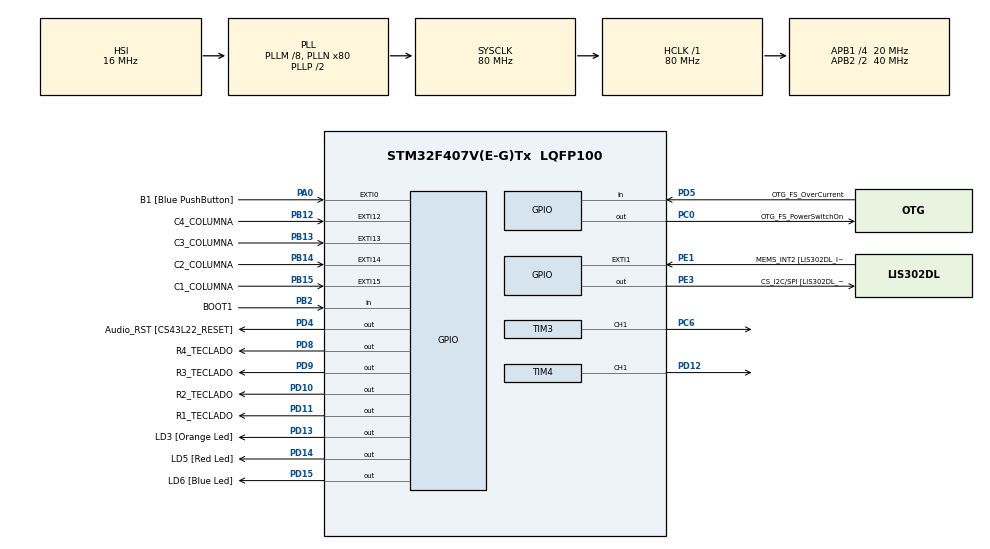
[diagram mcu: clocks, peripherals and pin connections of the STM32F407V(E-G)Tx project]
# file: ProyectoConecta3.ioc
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Dma.Request0=TIM4_CH1
Dma.Request1=TIM8_CH4/TRIG/COM
Dma.TIM4_CH1.0.Direction=DMA_MEMORY_TO_PERIPH
Dma.TIM4_CH1.0.FIFOMode=DMA_FIFOMODE_DISABLE
Dma.TIM4_CH1.0.Instance=DMA1_Stream0
Dma.TIM4_CH1.0.MemDataAlignment=DMA_MDATAALIGN_HALFWORD
Dma.TIM4_CH1.0.MemInc=DMA_MINC_ENABLE
Dma.TIM4_CH1.0.Mode=DMA_NORMAL
Dma.TIM4_CH1.0.PeriphDataAlignment=DMA_PDATAALIGN_HALFWORD
Dma.TIM4_CH1.0.PeriphInc=DMA_PINC_DISABLE
Dma.TIM4_CH1.0.Priority=DMA_PRIORITY_HIGH
Dma.TIM8_CH4/TRIG/COM.1.Direction=DMA_PERIPH_TO_MEMORY
Dma.TIM8_CH4/TRIG/COM.1.FIFOMode=DMA_FIFOMODE_DISABLE
Dma.TIM8_CH4/TRIG/COM.1.Instance=DMA2_Stream7
Dma.TIM8_CH4/TRIG/COM.1.MemDataAlignment=DMA_MDATAALIGN_HALFWORD
Dma.TIM8_CH4/TRIG/COM.1.MemInc=DMA_MINC_ENABLE
Dma.TIM8_CH4/TRIG/COM.1.Mode=DMA_NORMAL
Dma.TIM8_CH4/TRIG/COM.1.PeriphDataAlignment=DMA_PDATAALIGN_HALFWORD
Dma.TIM8_CH4/TRIG/COM.1.PeriphInc=DMA_PINC_DISABLE
Dma.TIM8_CH4/TRIG/COM.1.Priority=DMA_PRIORITY_LOW
Mcu.Family=STM32F4
Mcu.Name=STM32F407V(E-G)Tx
Mcu.Package=LQFP100
NVIC.DMA1_Stream0_IRQn=true\:0\:0\:false\:false\:true\:false\:true\:true
NVIC.DMA2_Stream7_IRQn=true\:0\:0\:false\:false\:true\:false\:true\:true
NVIC.EXTI0_IRQn=true\:0\:0\:false\:false\:true\:true\:true\:true
NVIC.EXTI15_10_IRQn=true\:0\:0\:false\:false\:true\:true\:true\:true
NVIC.PriorityGroup=NVIC_PRIORITYGROUP_0
NVIC.TIM8_TRG_COM_TIM14_IRQn=true\:0\:0\:false\:false\:true\:true\:true\:true
PA0-WKUP.GPIO_Label=B1 [Blue PushButton]
PA0-WKUP.Signal=GPXTI0
PA10.GPIO_Label=OTG_FS_ID
PA10.GPIO_Mode=GPIO_MODE_AF_PP
PA10.GPIO_PuPd=GPIO_NOPULL
PA10.GPIO_Speed=GPIO_SPEED_FREQ_LOW
PA10.Signal=USB_OTG_FS_ID
PA11.GPIO_Label=OTG_FS_DM
PA11.GPIO_Mode=GPIO_MODE_AF_PP
PA11.GPIO_PuPd=GPIO_NOPULL
PA11.GPIO_Speed=GPIO_SPEED_FREQ_LOW
PA11.Signal=USB_OTG_FS_DM
PA12.GPIO_Label=OTG_FS_DP
PA12.GPIO_Mode=GPIO_MODE_AF_PP
PA12.GPIO_PuPd=GPIO_NOPULL
PA12.GPIO_Speed=GPIO_SPEED_FREQ_LOW
PA12.Signal=USB_OTG_FS_DP
PA13.GPIO_Label=SWDIO
PA13.Signal=SYS_JTMS-SWDIO
PA14.GPIO_Label=SWCLK
PA14.Signal=SYS_JTCK-SWCLK
PA4.GPIO_Label=I2S3_WS [CS43L22_LRCK]
PA4.GPIO_Mode=GPIO_MODE_AF_PP
PA4.GPIO_PuPd=GPIO_NOPULL
PA4.GPIO_Speed=GPIO_SPEED_FREQ_LOW
PA4.Signal=I2S3_WS
PA5.GPIO_Label=SPI1_SCK [LIS302DL_SCL/SPC]
PA5.GPIO_Mode=GPIO_MODE_AF_PP
PA5.GPIO_PuPd=GPIO_NOPULL
PA5.GPIO_Speed=GPIO_SPEED_FREQ_LOW
PA5.Signal=SPI1_SCK
PA9.GPIO_Label=VBUS_FS
PA9.GPIO_Mode=GPIO_MODE_INPUT
PA9.GPIO_PuPd=GPIO_NOPULL
PA9.Signal=USB_OTG_FS_VBUS
PB10.GPIO_Label=CLK_IN [MP45DT02_CLK]
PB10.GPIO_Mode=GPIO_MODE_AF_PP
PB10.GPIO_PuPd=GPIO_NOPULL
PB10.GPIO_Speed=GPIO_SPEED_FREQ_LOW
PB10.Signal=I2S2_CK
PB12.GPIO_Label=C4_COLUMNA
PB12.GPIO_ModeDefaultEXTI=GPIO_MODE_IT_FALLING
PB12.GPIO_PuPd=GPIO_PULLUP
PB12.Signal=GPXTI12
PB13.GPIO_Label=C3_COLUMNA
PB13.GPIO_ModeDefaultEXTI=GPIO_MODE_IT_FALLING
PB13.GPIO_PuPd=GPIO_PULLUP
PB13.Signal=GPXTI13
PB14.GPIO_Label=C2_COLUMNA
PB14.GPIO_ModeDefaultEXTI=GPIO_MODE_IT_FALLING
PB14.GPIO_PuPd=GPIO_PULLUP
PB14.Signal=GPXTI14
PB15.GPIO_Label=C1_COLUMNA
PB15.GPIO_ModeDefaultEXTI=GPIO_MODE_IT_FALLING
PB15.GPIO_PuPd=GPIO_PULLUP
PB15.Signal=GPXTI15
PB2.GPIO_Label=BOOT1
PB2.GPIO_Mode=GPIO_MODE_INPUT
PB2.GPIO_PuPd=GPIO_NOPULL
PB2.Signal=GPIO_Input
PB3.GPIO_Label=SWO
PB3.Signal=SYS_JTDO-SWO
PB6.GPIO_Label=Audio_SCL [CS43L22_SCL]
PB6.GPIO_Mode=GPIO_MODE_AF_OD
PB6.GPIO_PuPd=GPIO_NOPULL
PB6.GPIO_Speed=GPIO_SPEED_FREQ_LOW
PB6.Signal=I2C1_SCL
PC0.GPIO_Label=OTG_FS_PowerSwitchOn
PC0.GPIO_PuPd=GPIO_NOPULL
PC0.GPIO_Speed=GPIO_SPEED_FREQ_LOW
PC0.PinState=GPIO_PIN_SET
PC0.Signal=GPIO_Output
PC10.GPIO_Label=I2S3_SCK [CS43L22_SCLK]
PC10.GPIO_Mode=GPIO_MODE_AF_PP
PC10.GPIO_PuPd=GPIO_NOPULL
PC10.GPIO_Speed=GPIO_SPEED_FREQ_LOW
PC10.Signal=I2S3_CK
PC12.GPIO_Label=I2S3_SD [CS43L22_SDIN]
PC12.GPIO_Mode=GPIO_MODE_AF_PP
PC12.GPIO_PuPd=GPIO_NOPULL
PC12.GPIO_Speed=GPIO_SPEED_FREQ_LOW
PC12.Signal=I2S3_SD
PC14-OSC32_IN.GPIO_Label=PC14-OSC32_IN
PC14-OSC32_IN.Signal=RCC_OSC32_IN
PC15-OSC32_OUT.GPIO_Label=PC15-OSC32_OUT
PC15-OSC32_OUT.Signal=RCC_OSC32_OUT
PC3.GPIO_Label=PDM_OUT [MP45DT02_DOUT]
PC3.GPIO_Mode=GPIO_MODE_AF_PP
PC3.GPIO_PuPd=GPIO_NOPULL
PC3.GPIO_Speed=GPIO_SPEED_FREQ_LOW
PC3.Signal=I2S2_SD
PC6.Signal=S_TIM3_CH1
PC7.GPIO_Label=I2S3_MCK [CS43L22_MCLK]
PC7.GPIO_Mode=GPIO_MODE_AF_PP
PC7.GPIO_PuPd=GPIO_NOPULL
PC7.GPIO_Speed=GPIO_SPEED_FREQ_LOW
PC7.Signal=I2S3_MCK
PD10.GPIO_Label=R2_TECLADO
PD10.GPIO_ModeDefaultOutputPP=GPIO_MODE_OUTPUT_OD
PD10.GPIO_PuPd=GPIO_NOPULL
PD10.Signal=GPIO_Output
PD11.GPIO_Label=R1_TECLADO
PD11.GPIO_ModeDefaultOutputPP=GPIO_MODE_OUTPUT_OD
PD11.GPIO_PuPd=GPIO_NOPULL
PD11.Signal=GPIO_Output
PD12.GPIO_Speed=GPIO_SPEED_FREQ_HIGH
PD12.Signal=S_TIM4_CH1
PD13.GPIO_Label=LD3 [Orange Led]
PD13.GPIO_PuPd=GPIO_NOPULL
PD13.GPIO_Speed=GPIO_SPEED_FREQ_LOW
PD13.Signal=GPIO_Output
PD14.GPIO_Label=LD5 [Red Led]
PD14.GPIO_PuPd=GPIO_NOPULL
PD14.GPIO_Speed=GPIO_SPEED_FREQ_LOW
PD14.Signal=GPIO_Output
PD15.GPIO_Label=LD6 [Blue Led]
PD15.GPIO_PuPd=GPIO_NOPULL
PD15.GPIO_Speed=GPIO_SPEED_FREQ_LOW
PD15.Signal=GPIO_Output
PD4.GPIO_Label=Audio_RST [CS43L22_RESET]
PD4.GPIO_PuPd=GPIO_NOPULL
PD4.GPIO_Speed=GPIO_SPEED_FREQ_LOW
PD4.Signal=GPIO_Output
PD5.GPIO_Label=OTG_FS_OverCurrent
PD5.GPIO_Mode=GPIO_MODE_INPUT
PD5.GPIO_PuPd=GPIO_NOPULL
PD5.Signal=GPIO_Input
PD8.GPIO_Label=R4_TECLADO
PD8.GPIO_ModeDefaultOutputPP=GPIO_MODE_OUTPUT_OD
PD8.GPIO_PuPd=GPIO_NOPULL
PD8.Signal=GPIO_Output
PD9.GPIO_Label=R3_TECLADO
PD9.GPIO_ModeDefaultOutputPP=GPIO_MODE_OUTPUT_OD
PD9.GPIO_PuPd=GPIO_NOPULL
PD9.Signal=GPIO_Output
PE1.GPIO_Label=MEMS_INT2 [LIS302DL_INT2]
PE1.GPIO_ModeDefaultEXTI=GPIO_MODE_EVT_RISING
PE1.GPIO_PuPd=GPIO_NOPULL
PE1.Signal=GPXTI1
PE3.GPIO_Label=CS_I2C/SPI [LIS302DL_CS_I2C/SPI]
PE3.GPIO_PuPd=GPIO_NOPULL
PE3.GPIO_Speed=GPIO_SPEED_FREQ_LOW
PE3.Signal=GPIO_Output
PE7.Signal=S_TIM1_ETR
PH0-OSC_IN.GPIO_Label=PH0-OSC_IN
PH0-OSC_IN.Signal=RCC_OSC_IN
PH1-OSC_OUT.GPIO_Label=PH1-OSC_OUT
PH1-OSC_OUT.Signal=RCC_OSC_OUT
ProjectManager.HeapSize=0x200
ProjectManager.StackSize=0x400
ProjectManager.TargetToolchain=STM32CubeIDE
RCC.48MHZClocksFreq_Value=22857142.85714286
RCC.AHBFreq_Value=80000000
RCC.APB1CLKDivider=RCC_HCLK_DIV4
RCC.APB1Freq_Value=20000000
RCC.APB1TimFreq_Value=40000000
RCC.APB2CLKDivider=RCC_HCLK_DIV2
RCC.APB2Freq_Value=40000000
RCC.APB2TimFreq_Value=80000000
RCC.CortexFreq_Value=80000000
RCC.HCLKFreq_Value=80000000
RCC.HSE_VALUE=8000000
RCC.HSI_VALUE=16000000
RCC.LSE_VALUE=32768
RCC.PLLM=8
RCC.PLLN=80
RCC.PLLQ=7
RCC.SYSCLKFreq_VALUE=80000000
RCC.SYSCLKSource=RCC_SYSCLKSOURCE_PLLCLK
RCC.VCOOutputFreq_Value=160000000
SH.S_TIM1_ETR.0=TIM1_ETR
SH.S_TIM3_CH1.0=TIM3_CH1,PWM Generation1 CH1
SH.S_TIM4_CH1.0=TIM4_CH1,PWM Generation1 CH1
TIM14.AutoReloadPreload=TIM_AUTORELOAD_PRELOAD_ENABLE
TIM14.Period=9
TIM14.Prescaler=39999
TIM3.AutoReloadPreload=TIM_AUTORELOAD_PRELOAD_ENABLE
TIM3.Channel-PWM\ Generation1\ CH1=TIM_CHANNEL_1
TIM3.Period=28408
TIM3.Prescaler=2
TIM4.Channel-PWM\ Generation1\ CH1=TIM_CHANNEL_1
TIM4.Period=49
VP_TIM14_VS_ClockSourceINT.Mode=Enable_Timer
VP_TIM1_VS_ClockSourceINT.Mode=Internal
VP_TIM3_VS_ClockSourceINT.Mode=Internal
VP_TIM4_VS_ClockSourceINT.Mode=Internal
VP_TIM8_VS_ClockSourceINT.Mode=Internal
board=STM32F407G-DISC1

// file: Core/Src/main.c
/* USER CODE BEGIN Header */
/**
  ******************************************************************************
  * @file           : main.c
  * @brief          : Main program body
  ******************************************************************************
  * @attention
  *
  * Copyright (c) 2026 STMicroelectronics.
  * All rights reserved.
  *
  * This software is licensed under terms that can be found in the LICENSE file
  * in the root directory of this software component.
  * If no LICENSE file comes with this software, it is provided AS-IS.
  *
  ******************************************************************************
  */
/* USER CODE END Header */
#include "main.h"

/* USER CODE BEGIN Includes */
#include "Teclado.h"
#include "Leds.h"
#include "Conecta3.h"
/* USER CODE END Includes */

TIM_HandleTypeDef htim1;
TIM_HandleTypeDef htim3;
TIM_HandleTypeDef htim4;
TIM_HandleTypeDef htim8;
TIM_HandleTypeDef htim14;
DMA_HandleTypeDef hdma_tim4_ch1;
DMA_HandleTypeDef hdma_tim8_ch4_trig_com;

void SystemClock_Config(void);
static void MX_GPIO_Init(void);
static void MX_DMA_Init(void);
static void MX_TIM4_Init(void);
static void MX_TIM1_Init(void);
static void MX_TIM8_Init(void);
static void MX_TIM14_Init(void);
static void MX_TIM3_Init(void);

int main(void)
{

  /* MCU Configuration--------------------------------------------------------*/

  /* Reset of all peripherals, Initializes the Flash interface and the Systick. */
  HAL_Init();

  /* Configure the system clock */
  SystemClock_Config();

  /* Initialize all configured peripherals */
  MX_GPIO_Init();
  MX_DMA_Init();
  MX_TIM4_Init();
  MX_TIM1_Init();
  MX_TIM8_Init();
  MX_TIM14_Init();
  MX_TIM3_Init();
  /* USER CODE BEGIN 2 */

   // HAL_Delay(50); // Le damos tiempo a los LEDs para despertar

    Teclado_Init();
    Juego_Init();  // Esto inicializa la matriz virtual y la física
   //HAL_TIM_Base_Start_IT(&htim14);

  /* USER CODE END 2 */

  /* Infinite loop */
  /* USER CODE BEGIN WHILE */
    while (1)
      {
    	/* Actualiza los registros internos de sensado del teclado matricial */
    	      Teclado_Update();

    	      /* Tarea asincrónica del refresco gráfico y rutinas temporales de juego */
    	      Juego_Actualizar();

    	      /* Captura el evento de la última pulsación filtrada */
    	      uint8_t tecla = Teclado_GetUltimaTecla();

    	      /* Despacha el código de la tecla hacia el subsistema lógico */
    	      if (tecla != 0) {
    	          Juego_ProcesarEntrada(tecla);
    	      }
      }
    /* USER CODE END WHILE */

}

void SystemClock_Config(void)
{
  RCC_OscInitTypeDef RCC_OscInitStruct = {0};
  RCC_ClkInitTypeDef RCC_ClkInitStruct = {0};

  /** Configure the main internal regulator output voltage
  */
  __HAL_RCC_PWR_CLK_ENABLE();
  __HAL_PWR_VOLTAGESCALING_CONFIG(PWR_REGULATOR_VOLTAGE_SCALE1);

  /** Initializes the RCC Oscillators according to the specified parameters
  * in the RCC_OscInitTypeDef structure.
  */
  RCC_OscInitStruct.OscillatorType = RCC_OSCILLATORTYPE_HSI;
  RCC_OscInitStruct.HSIState = RCC_HSI_ON;
  RCC_OscInitStruct.HSICalibrationValue = RCC_HSICALIBRATION_DEFAULT;
  RCC_OscInitStruct.PLL.PLLState = RCC_PLL_ON;
  RCC_OscInitStruct.PLL.PLLSource = RCC_PLLSOURCE_HSI;
  RCC_OscInitStruct.PLL.PLLM = 8;
  RCC_OscInitStruct.PLL.PLLN = 80;
  RCC_OscInitStruct.PLL.PLLP = RCC_PLLP_DIV2;
  RCC_OscInitStruct.PLL.PLLQ = 7;
  if (HAL_RCC_OscConfig(&RCC_OscInitStruct) != HAL_OK)
  {
    Error_Handler();
  }

  /** Initializes the CPU, AHB and APB buses clocks
  */
  RCC_ClkInitStruct.ClockType = RCC_CLOCKTYPE_HCLK|RCC_CLOCKTYPE_SYSCLK
                              |RCC_CLOCKTYPE_PCLK1|RCC_CLOCKTYPE_PCLK2;
  RCC_ClkInitStruct.SYSCLKSource = RCC_SYSCLKSOURCE_PLLCLK;
  RCC_ClkInitStruct.AHBCLKDivider = RCC_SYSCLK_DIV1;
  RCC_ClkInitStruct.APB1CLKDivider = RCC_HCLK_DIV4;
  RCC_ClkInitStruct.APB2CLKDivider = RCC_HCLK_DIV2;

  if (HAL_RCC_ClockConfig(&RCC_ClkInitStruct, FLASH_LATENCY_2) != HAL_OK)
  {
    Error_Handler();
  }
}

static void MX_TIM1_Init(void)
{

  TIM_ClockConfigTypeDef sClockSourceConfig = {0};
  TIM_MasterConfigTypeDef sMasterConfig = {0};

  htim1.Instance = TIM1;
  htim1.Init.Prescaler = 0;
  htim1.Init.CounterMode = TIM_COUNTERMODE_UP;
  htim1.Init.Period = 65535;
  htim1.Init.ClockDivision = TIM_CLOCKDIVISION_DIV1;
  htim1.Init.RepetitionCounter = 0;
  htim1.Init.AutoReloadPreload = TIM_AUTORELOAD_PRELOAD_DISABLE;
  if (HAL_TIM_Base_Init(&htim1) != HAL_OK)
  {
    Error_Handler();
  }
  sClockSourceConfig.ClockSource = TIM_CLOCKSOURCE_INTERNAL;
  if (HAL_TIM_ConfigClockSource(&htim1, &sClockSourceConfig) != HAL_OK)
  {
    Error_Handler();
  }
  sMasterConfig.MasterOutputTrigger = TIM_TRGO_RESET;
  sMasterConfig.MasterSlaveMode = TIM_MASTERSLAVEMODE_DISABLE;
  if (HAL_TIMEx_MasterConfigSynchronization(&htim1, &sMasterConfig) != HAL_OK)
  {
    Error_Handler();
  }

}

static void MX_TIM3_Init(void)
{

  TIM_ClockConfigTypeDef sClockSourceConfig = {0};
  TIM_MasterConfigTypeDef sMasterConfig = {0};
  TIM_OC_InitTypeDef sConfigOC = {0};

  htim3.Instance = TIM3;
  htim3.Init.Prescaler = 2;
  htim3.Init.CounterMode = TIM_COUNTERMODE_UP;
  htim3.Init.Period = 28408;
  htim3.Init.ClockDivision = TIM_CLOCKDIVISION_DIV1;
  htim3.Init.AutoReloadPreload = TIM_AUTORELOAD_PRELOAD_ENABLE;
  if (HAL_TIM_Base_Init(&htim3) != HAL_OK)
  {
    Error_Handler();
  }
  sClockSourceConfig.ClockSource = TIM_CLOCKSOURCE_INTERNAL;
  if (HAL_TIM_ConfigClockSource(&htim3, &sClockSourceConfig) != HAL_OK)
  {
    Error_Handler();
  }
  if (HAL_TIM_PWM_Init(&htim3) != HAL_OK)
  {
    Error_Handler();
  }
  sMasterConfig.MasterOutputTrigger = TIM_TRGO_RESET;
  sMasterConfig.MasterSlaveMode = TIM_MASTERSLAVEMODE_DISABLE;
  if (HAL_TIMEx_MasterConfigSynchronization(&htim3, &sMasterConfig) != HAL_OK)
  {
    Error_Handler();
  }
  sConfigOC.OCMode = TIM_OCMODE_PWM1;
  sConfigOC.Pulse = 0;
  sConfigOC.OCPolarity = TIM_OCPOLARITY_HIGH;
  sConfigOC.OCFastMode = TIM_OCFAST_DISABLE;
  if (HAL_TIM_PWM_ConfigChannel(&htim3, &sConfigOC, TIM_CHANNEL_1) != HAL_OK)
  {
    Error_Handler();
  }
  HAL_TIM_MspPostInit(&htim3);

}

static void MX_TIM4_Init(void)
{

  TIM_ClockConfigTypeDef sClockSourceConfig = {0};
  TIM_MasterConfigTypeDef sMasterConfig = {0};
  TIM_OC_InitTypeDef sConfigOC = {0};

  htim4.Instance = TIM4;
  htim4.Init.Prescaler = 0;
  htim4.Init.CounterMode = TIM_COUNTERMODE_UP;
  htim4.Init.Period = 49;
  htim4.Init.ClockDivision = TIM_CLOCKDIVISION_DIV1;
  htim4.Init.AutoReloadPreload = TIM_AUTORELOAD_PRELOAD_DISABLE;
  if (HAL_TIM_Base_Init(&htim4) != HAL_OK)
  {
    Error_Handler();
  }
  sClockSourceConfig.ClockSource = TIM_CLOCKSOURCE_INTERNAL;
  if (HAL_TIM_ConfigClockSource(&htim4, &sClockSourceConfig) != HAL_OK)
  {
    Error_Handler();
  }
  if (HAL_TIM_PWM_Init(&htim4) != HAL_OK)
  {
    Error_Handler();
  }
  sMasterConfig.MasterOutputTrigger = TIM_TRGO_RESET;
  sMasterConfig.MasterSlaveMode = TIM_MASTERSLAVEMODE_DISABLE;
  if (HAL_TIMEx_MasterConfigSynchronization(&htim4, &sMasterConfig) != HAL_OK)
  {
    Error_Handler();
  }
  sConfigOC.OCMode = TIM_OCMODE_PWM1;
  sConfigOC.Pulse = 0;
  sConfigOC.OCPolarity = TIM_OCPOLARITY_HIGH;
  sConfigOC.OCFastMode = TIM_OCFAST_DISABLE;
  if (HAL_TIM_PWM_ConfigChannel(&htim4, &sConfigOC, TIM_CHANNEL_1) != HAL_OK)
  {
    Error_Handler();
  }
  HAL_TIM_MspPostInit(&htim4);

}

static void MX_TIM8_Init(void)
{

  TIM_ClockConfigTypeDef sClockSourceConfig = {0};
  TIM_MasterConfigTypeDef sMasterConfig = {0};

  htim8.Instance = TIM8;
  htim8.Init.Prescaler = 0;
  htim8.Init.CounterMode = TIM_COUNTERMODE_UP;
  htim8.Init.Period = 65535;
  htim8.Init.ClockDivision = TIM_CLOCKDIVISION_DIV1;
  htim8.Init.RepetitionCounter = 0;
  htim8.Init.AutoReloadPreload = TIM_AUTORELOAD_PRELOAD_DISABLE;
  if (HAL_TIM_Base_Init(&htim8) != HAL_OK)
  {
    Error_Handler();
  }
  sClockSourceConfig.ClockSource = TIM_CLOCKSOURCE_INTERNAL;
  if (HAL_TIM_ConfigClockSource(&htim8, &sClockSourceConfig) != HAL_OK)
  {
    Error_Handler();
  }
  sMasterConfig.MasterOutputTrigger = TIM_TRGO_RESET;
  sMasterConfig.MasterSlaveMode = TIM_MASTERSLAVEMODE_DISABLE;
  if (HAL_TIMEx_MasterConfigSynchronization(&htim8, &sMasterConfig) != HAL_OK)
  {
    Error_Handler();
  }

}

static void MX_TIM14_Init(void)
{

  htim14.Instance = TIM14;
  htim14.Init.Prescaler = 39999;
  htim14.Init.CounterMode = TIM_COUNTERMODE_UP;
  htim14.Init.Period = 9;
  htim14.Init.ClockDivision = TIM_CLOCKDIVISION_DIV1;
  htim14.Init.AutoReloadPreload = TIM_AUTORELOAD_PRELOAD_ENABLE;
  if (HAL_TIM_Base_Init(&htim14) != HAL_OK)
  {
    Error_Handler();
  }

}

static void MX_DMA_Init(void)
{

  /* DMA controller clock enable */
  __HAL_RCC_DMA1_CLK_ENABLE();
  __HAL_RCC_DMA2_CLK_ENABLE();

  /* DMA interrupt init */
  /* DMA1_Stream0_IRQn interrupt configuration */
  HAL_NVIC_SetPriority(DMA1_Stream0_IRQn, 0, 0);
  HAL_NVIC_EnableIRQ(DMA1_Stream0_IRQn);
  /* DMA2_Stream7_IRQn interrupt configuration */
  HAL_NVIC_SetPriority(DMA2_Stream7_IRQn, 0, 0);
  HAL_NVIC_EnableIRQ(DMA2_Stream7_IRQn);

}

static void MX_GPIO_Init(void)
{
  GPIO_InitTypeDef GPIO_InitStruct = {0};

  /* GPIO Ports Clock Enable */
  __HAL_RCC_GPIOE_CLK_ENABLE();
  __HAL_RCC_GPIOC_CLK_ENABLE();
  __HAL_RCC_GPIOH_CLK_ENABLE();
  __HAL_RCC_GPIOA_CLK_ENABLE();
  __HAL_RCC_GPIOB_CLK_ENABLE();
  __HAL_RCC_GPIOD_CLK_ENABLE();

  /*Configure GPIO pin Output Level */
  HAL_GPIO_WritePin(CS_I2C_SPI_GPIO_Port, CS_I2C_SPI_Pin, GPIO_PIN_RESET);

  /*Configure GPIO pin Output Level */
  HAL_GPIO_WritePin(OTG_FS_PowerSwitchOn_GPIO_Port, OTG_FS_PowerSwitchOn_Pin, GPIO_PIN_SET);

  /*Configure GPIO pin Output Level */
  HAL_GPIO_WritePin(GPIOD, R4_TECLADO_Pin|R3_TECLADO_Pin|R2_TECLADO_Pin|R1_TECLADO_Pin
                          |LD3_Pin|LD5_Pin|LD6_Pin|Audio_RST_Pin, GPIO_PIN_RESET);

  /*Configure GPIO pin : CS_I2C_SPI_Pin */
  GPIO_InitStruct.Pin = CS_I2C_SPI_Pin;
  GPIO_InitStruct.Mode = GPIO_MODE_OUTPUT_PP;
  GPIO_InitStruct.Pull = GPIO_NOPULL;
  GPIO_InitStruct.Speed = GPIO_SPEED_FREQ_LOW;
  HAL_GPIO_Init(CS_I2C_SPI_GPIO_Port, &GPIO_InitStruct);

  /*Configure GPIO pin : OTG_FS_PowerSwitchOn_Pin */
  GPIO_InitStruct.Pin = OTG_FS_PowerSwitchOn_Pin;
  GPIO_InitStruct.Mode = GPIO_MODE_OUTPUT_PP;
  GPIO_InitStruct.Pull = GPIO_NOPULL;
  GPIO_InitStruct.Speed = GPIO_SPEED_FREQ_LOW;
  HAL_GPIO_Init(OTG_FS_PowerSwitchOn_GPIO_Port, &GPIO_InitStruct);

  /*Configure GPIO pin : PDM_OUT_Pin */
  GPIO_InitStruct.Pin = PDM_OUT_Pin;
  GPIO_InitStruct.Mode = GPIO_MODE_AF_PP;
  GPIO_InitStruct.Pull = GPIO_NOPULL;
  GPIO_InitStruct.Speed = GPIO_SPEED_FREQ_LOW;
  GPIO_InitStruct.Alternate = GPIO_AF5_SPI2;
  HAL_GPIO_Init(PDM_OUT_GPIO_Port, &GPIO_InitStruct);

  /*Configure GPIO pin : B1_Pin */
  GPIO_InitStruct.Pin = B1_Pin;
  GPIO_InitStruct.Mode = GPIO_MODE_IT_RISING;
  GPIO_InitStruct.Pull = GPIO_NOPULL;
  HAL_GPIO_Init(B1_GPIO_Port, &GPIO_InitStruct);

  /*Configure GPIO pin : I2S3_WS_Pin */
  GPIO_InitStruct.Pin = I2S3_WS_Pin;
  GPIO_InitStruct.Mode = GPIO_MODE_AF_PP;
  GPIO_InitStruct.Pull = GPIO_NOPULL;
  GPIO_InitStruct.Speed = GPIO_SPEED_FREQ_LOW;
  GPIO_InitStruct.Alternate = GPIO_AF6_SPI3;
  HAL_GPIO_Init(I2S3_WS_GPIO_Port, &GPIO_InitStruct);

  /*Configure GPIO pin : SPI1_SCK_Pin */
  GPIO_InitStruct.Pin = SPI1_SCK_Pin;
  GPIO_InitStruct.Mode = GPIO_MODE_AF_PP;
  GPIO_InitStruct.Pull = GPIO_NOPULL;
  GPIO_InitStruct.Speed = GPIO_SPEED_FREQ_LOW;
  GPIO_InitStruct.Alternate = GPIO_AF5_SPI1;
  HAL_GPIO_Init(SPI1_SCK_GPIO_Port, &GPIO_InitStruct);

  /*Configure GPIO pin : BOOT1_Pin */
  GPIO_InitStruct.Pin = BOOT1_Pin;
  GPIO_InitStruct.Mode = GPIO_MODE_INPUT;
  GPIO_InitStruct.Pull = GPIO_NOPULL;
  HAL_GPIO_Init(BOOT1_GPIO_Port, &GPIO_InitStruct);

  /*Configure GPIO pin : CLK_IN_Pin */
  GPIO_InitStruct.Pin = CLK_IN_Pin;
  GPIO_InitStruct.Mode = GPIO_MODE_AF_PP;
  GPIO_InitStruct.Pull = GPIO_NOPULL;
  GPIO_InitStruct.Speed = GPIO_SPEED_FREQ_LOW;
  GPIO_InitStruct.Alternate = GPIO_AF5_SPI2;
  HAL_GPIO_Init(CLK_IN_GPIO_Port, &GPIO_InitStruct);

  /*Configure GPIO pins : C4_COLUMNA_Pin C3_COLUMNA_Pin C2_COLUMNA_Pin C1_COLUMNA_Pin */
  GPIO_InitStruct.Pin = C4_COLUMNA_Pin|C3_COLUMNA_Pin|C2_COLUMNA_Pin|C1_COLUMNA_Pin;
  GPIO_InitStruct.Mode = GPIO_MODE_IT_FALLING;
  GPIO_InitStruct.Pull = GPIO_PULLUP;
  HAL_GPIO_Init(GPIOB, &GPIO_InitStruct);

  /*Configure GPIO pins : R4_TECLADO_Pin R3_TECLADO_Pin R2_TECLADO_Pin R1_TECLADO_Pin */
  GPIO_InitStruct.Pin = R4_TECLADO_Pin|R3_TECLADO_Pin|R2_TECLADO_Pin|R1_TECLADO_Pin;
  GPIO_InitStruct.Mode = GPIO_MODE_OUTPUT_OD;
  GPIO_InitStruct.Pull = GPIO_NOPULL;
  GPIO_InitStruct.Speed = GPIO_SPEED_FREQ_LOW;
  HAL_GPIO_Init(GPIOD, &GPIO_InitStruct);

  /*Configure GPIO pins : LD3_Pin LD5_Pin LD6_Pin Audio_RST_Pin */
  GPIO_InitStruct.Pin = LD3_Pin|LD5_Pin|LD6_Pin|Audio_RST_Pin;
  GPIO_InitStruct.Mode = GPIO_MODE_OUTPUT_PP;
  GPIO_InitStruct.Pull = GPIO_NOPULL;
  GPIO_InitStruct.Speed = GPIO_SPEED_FREQ_LOW;
  HAL_GPIO_Init(GPIOD, &GPIO_InitStruct);

  /*Configure GPIO pins : I2S3_MCK_Pin I2S3_SCK_Pin I2S3_SD_Pin */
  GPIO_InitStruct.Pin = I2S3_MCK_Pin|I2S3_SCK_Pin|I2S3_SD_Pin;
  GPIO_InitStruct.Mode = GPIO_MODE_AF_PP;
  GPIO_InitStruct.Pull = GPIO_NOPULL;
  GPIO_InitStruct.Speed = GPIO_SPEED_FREQ_LOW;
  GPIO_InitStruct.Alternate = GPIO_AF6_SPI3;
  HAL_GPIO_Init(GPIOC, &GPIO_InitStruct);

  /*Configure GPIO pin : VBUS_FS_Pin */
  GPIO_InitStruct.Pin = VBUS_FS_Pin;
  GPIO_InitStruct.Mode = GPIO_MODE_INPUT;
  GPIO_InitStruct.Pull = GPIO_NOPULL;
  HAL_GPIO_Init(VBUS_FS_GPIO_Port, &GPIO_InitStruct);

  /*Configure GPIO pins : OTG_FS_ID_Pin OTG_FS_DM_Pin OTG_FS_DP_Pin */
  GPIO_InitStruct.Pin = OTG_FS_ID_Pin|OTG_FS_DM_Pin|OTG_FS_DP_Pin;
  GPIO_InitStruct.Mode = GPIO_MODE_AF_PP;
  GPIO_InitStruct.Pull = GPIO_NOPULL;
  GPIO_InitStruct.Speed = GPIO_SPEED_FREQ_LOW;
  GPIO_InitStruct.Alternate = GPIO_AF10_OTG_FS;
  HAL_GPIO_Init(GPIOA, &GPIO_InitStruct);

  /*Configure GPIO pin : OTG_FS_OverCurrent_Pin */
  GPIO_InitStruct.Pin = OTG_FS_OverCurrent_Pin;
  GPIO_InitStruct.Mode = GPIO_MODE_INPUT;
  GPIO_InitStruct.Pull = GPIO_NOPULL;
  HAL_GPIO_Init(OTG_FS_OverCurrent_GPIO_Port, &GPIO_InitStruct);

  /*Configure GPIO pin : Audio_SCL_Pin */
  GPIO_InitStruct.Pin = Audio_SCL_Pin;
  GPIO_InitStruct.Mode = GPIO_MODE_AF_OD;
  GPIO_InitStruct.Pull = GPIO_NOPULL;
  GPIO_InitStruct.Speed = GPIO_SPEED_FREQ_LOW;
  GPIO_InitStruct.Alternate = GPIO_AF4_I2C1;
  HAL_GPIO_Init(Audio_SCL_GPIO_Port, &GPIO_InitStruct);

  /*Configure GPIO pin : MEMS_INT2_Pin */
  GPIO_InitStruct.Pin = MEMS_INT2_Pin;
  GPIO_InitStruct.Mode = GPIO_MODE_EVT_RISING;
  GPIO_InitStruct.Pull = GPIO_NOPULL;
  HAL_GPIO_Init(MEMS_INT2_GPIO_Port, &GPIO_InitStruct);

  /* EXTI interrupt init*/
  HAL_NVIC_SetPriority(EXTI0_IRQn, 0, 0);
  HAL_NVIC_EnableIRQ(EXTI0_IRQn);

  HAL_NVIC_SetPriority(EXTI15_10_IRQn, 0, 0);
  HAL_NVIC_EnableIRQ(EXTI15_10_IRQn);

}

/* USER CODE BEGIN 4 */
void HAL_GPIO_EXTI_Callback(uint16_t GPIO_Pin) {
    // Le pasamos el pin que generó la interrupción a nuestro módulo
    Teclado_EXTI_Callback(GPIO_Pin);
}

/* USER CODE END 4 */

void Error_Handler(void)
{
  __disable_irq();
  while (1)
  {
  }
}
